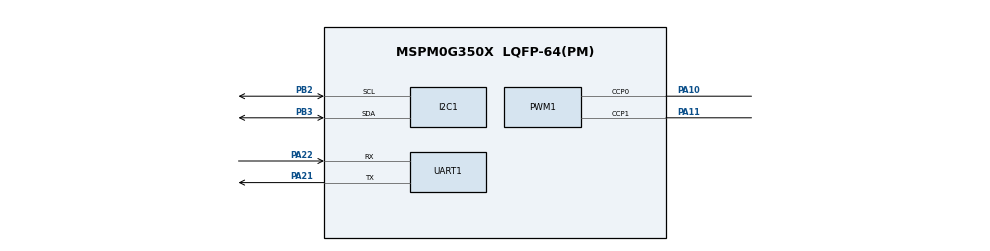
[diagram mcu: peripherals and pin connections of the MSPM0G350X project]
/**
 * @cliArgs --device "MSPM0G350X" --part "Default" --package "LQFP-64(PM)" --product "mspm0_sdk@2.05.01.00"
 * @versions {"tool":"1.24.0+4110"}
 */

/**
 * Import the modules used in this configuration.
 */
const I2C    = scripting.addModule("/ti/driverlib/I2C", {}, false);
const I2C1   = I2C.addInstance();
const PWM    = scripting.addModule("/ti/driverlib/PWM", {}, false);
const PWM1   = PWM.addInstance();
const SYSCTL = scripting.addModule("/ti/driverlib/SYSCTL");
const UART   = scripting.addModule("/ti/driverlib/UART", {}, false);
const UART1  = UART.addInstance();

/**
 * Write custom configuration values to the imported modules.
 */
const divider7       = system.clockTree["PLL_PDIV"];
divider7.divideValue = 2;

const divider9       = system.clockTree["UDIV"];
divider9.divideValue = 2;

const multiplier2         = system.clockTree["PLL_QDIV"];
multiplier2.multiplyValue = 5;

const mux8       = system.clockTree["HSCLKMUX"];
mux8.inputSelect = "HSCLKMUX_SYSPLL2X";

I2C1.$name                             = "I2C_OLED";
I2C1.basicEnableController             = true;
I2C1.basicControllerStandardBusSpeed   = "Fast";
I2C1.peripheral.$assign                = "I2C1";
I2C1.peripheral.sdaPin.$assign         = "PB3";
I2C1.peripheral.sclPin.$assign         = "PB2";
I2C1.sdaPinConfig.$name                = "ti_driverlib_gpio_GPIOPinGeneric0";
I2C1.sdaPinConfig.hideOutputInversion  = scripting.forceWrite(false);
I2C1.sdaPinConfig.onlyInternalResistor = scripting.forceWrite(false);
I2C1.sdaPinConfig.passedPeripheralType = scripting.forceWrite("Digital");
I2C1.sclPinConfig.$name                = "ti_driverlib_gpio_GPIOPinGeneric1";
I2C1.sclPinConfig.hideOutputInversion  = scripting.forceWrite(false);
I2C1.sclPinConfig.onlyInternalResistor = scripting.forceWrite(false);
I2C1.sclPinConfig.passedPeripheralType = scripting.forceWrite("Digital");

const Board = scripting.addModule("/ti/driverlib/Board", {}, false);

PWM1.timerStartTimer                    = true;
PWM1.clockPrescale                      = 200;
PWM1.timerCount                         = 8000;
PWM1.$name                              = "PWM_SERVO";
PWM1.peripheral.ccp0Pin.$assign         = "PA10";
PWM1.peripheral.ccp1Pin.$assign         = "PA11";
PWM1.PWM_CHANNEL_0.$name                = "ti_driverlib_pwm_PWMTimerCC0";
PWM1.PWM_CHANNEL_1.$name                = "ti_driverlib_pwm_PWMTimerCC1";
PWM1.ccp0PinConfig.direction            = scripting.forceWrite("OUTPUT");
PWM1.ccp0PinConfig.hideOutputInversion  = scripting.forceWrite(false);
PWM1.ccp0PinConfig.onlyInternalResistor = scripting.forceWrite(false);
PWM1.ccp0PinConfig.passedPeripheralType = scripting.forceWrite("Digital");
PWM1.ccp0PinConfig.$name                = "ti_driverlib_gpio_GPIOPinGeneric4";
PWM1.ccp1PinConfig.direction            = scripting.forceWrite("OUTPUT");
PWM1.ccp1PinConfig.hideOutputInversion  = scripting.forceWrite(false);
PWM1.ccp1PinConfig.onlyInternalResistor = scripting.forceWrite(false);
PWM1.ccp1PinConfig.passedPeripheralType = scripting.forceWrite("Digital");
PWM1.ccp1PinConfig.$name                = "ti_driverlib_gpio_GPIOPinGeneric5";

SYSCTL.forceDefaultClkConfig = true;
SYSCTL.clockTreeEn           = true;
scripting.suppress("For best practices when the CPUCLK is running at 32MHz and above, clear the flash status bit using DL_FlashCTL_executeClearStatus\\(\\) before executing any flash operation\\. Otherwise there may be false positives\\.", SYSCTL);

UART1.$name                            = "UART_OPENMV";
UART1.enabledInterrupts                = ["RX"];
UART1.peripheral.rxPin.$assign         = "PA22";
UART1.peripheral.txPin.$assign         = "PA21";
UART1.txPinConfig.direction            = scripting.forceWrite("OUTPUT");
UART1.txPinConfig.hideOutputInversion  = scripting.forceWrite(false);
UART1.txPinConfig.onlyInternalResistor = scripting.forceWrite(false);
UART1.txPinConfig.passedPeripheralType = scripting.forceWrite("Digital");
UART1.txPinConfig.$name                = "ti_driverlib_gpio_GPIOPinGeneric2";
UART1.rxPinConfig.hideOutputInversion  = scripting.forceWrite(false);
UART1.rxPinConfig.onlyInternalResistor = scripting.forceWrite(false);
UART1.rxPinConfig.passedPeripheralType = scripting.forceWrite("Digital");
UART1.rxPinConfig.$name                = "ti_driverlib_gpio_GPIOPinGeneric3";

/**
 * Pinmux solution for unlocked pins/peripherals. This ensures that minor changes to the automatic solver in a future
 * version of the tool will not impact the pinmux you originally saw.  These lines can be completely deleted in order to
 * re-solve from scratch.
 */
Board.peripheral.$suggestSolution          = "DEBUGSS";
Board.peripheral.swclkPin.$suggestSolution = "PA20";
Board.peripheral.swdioPin.$suggestSolution = "PA19";
PWM1.peripheral.$suggestSolution           = "TIMA1";
UART1.peripheral.$suggestSolution          = "UART2";
